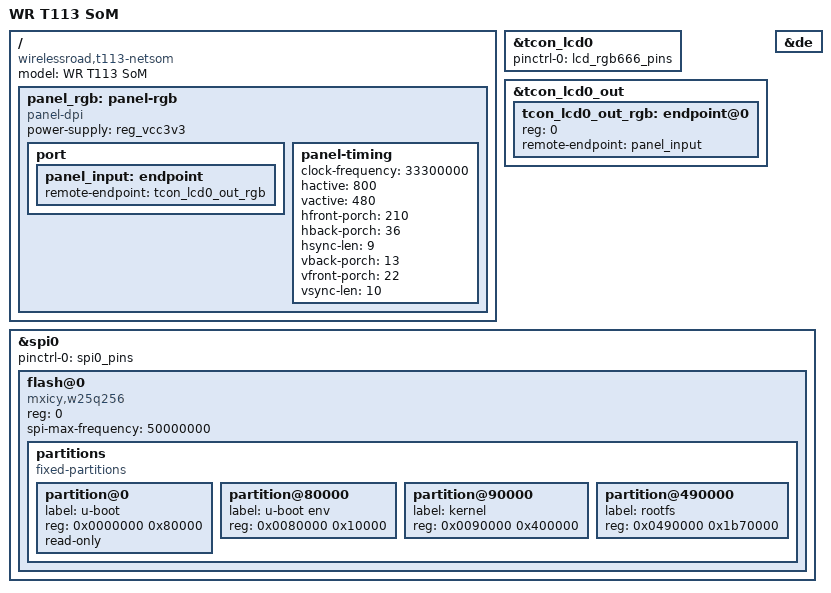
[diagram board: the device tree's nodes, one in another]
// SPDX-License-Identifier: (GPL-2.0+ OR MIT)
// Copyright (C) 2024 WirelessRoad.

/dts-v1/;

#include "sun8i-t113s-wr-netsom.dtsi"

/ {
	model = "WR T113 SoM";
	compatible = "wirelessroad,t113-netsom", "allwinner,sun8i-t113s";

    panel_rgb: panel-rgb {
        compatible = "panel-dpi";
        power-supply = <&reg_vcc3v3>;

        port {
          panel_input: endpoint {
            remote-endpoint = <&tcon_lcd0_out_rgb>;
          };
        };
        panel-timing {
            clock-frequency = <33300000>;
            hactive = <800>;
            vactive = <480>;
            hfront-porch = <210>;
            hback-porch = <36>;
            hsync-len = <9>;
            vback-porch = <13>;
            vfront-porch = <22>;
            vsync-len = <10>;
        };
    };
};

&tcon_lcd0 {
    	pinctrl-names = "default";
    	pinctrl-0 = <&lcd_rgb666_pins>;
    	status = "okay";
};

&tcon_lcd0_out {
    tcon_lcd0_out_rgb: endpoint@0 {
    		reg = <0>;
    		remote-endpoint = <&panel_input>;
    };
};

&de {
    status = "okay";
};

&spi0 {
    pinctrl-names = "default";
    pinctrl-0 = <&spi0_pins>;
    status = "okay";
    flash@0 {
        #address-cells = <1>;
        #size-cells = <1>;
        compatible = "mxicy,w25q256", "jedec,spi-nor";
        reg = <0>;
        spi-max-frequency = <50000000>;
        partitions {
            compatible = "fixed-partitions";
            #address-cells = <1>;
            #size-cells = <1>;
            partition@0 {
                label = "u-boot";
                reg = <0x0000000 0x80000>;
                read-only;
            };
            partition@80000 {
                label = "u-boot env";
                reg = <0x0080000 0x10000>;
            };
            partition@90000 {
                label = "kernel";
                reg = <0x0090000 0x400000>;
            };
            partition@490000 {
                label = "rootfs";
                reg = <0x0490000 0x1b70000>;
            };
        };
    };
};
